# M2354 register map
File version: 1.0
Registers are 32-bit, read-write, reset 0x0 unless marked. A register's access mark holds for its fields unless they carry their own. Offsets are from the block's base; [hi:lo] are bit positions; {n}, {i} and the like mark numbered series.

## KS — KS Register Map
Base 0x40035000
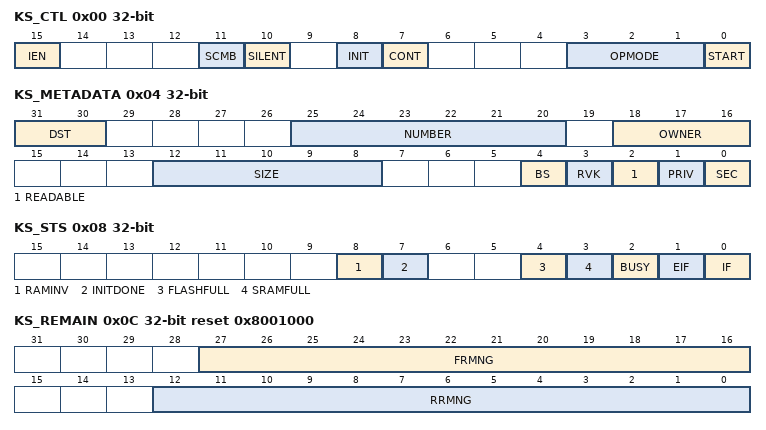
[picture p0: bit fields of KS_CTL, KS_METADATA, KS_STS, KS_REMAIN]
0x00 KS_CTL — Key Store Control Register
  [15] IEN — Key Store Interrupt Enable Bit
    0=Key Store Interrupt Disabled; 1=Key Store Interrupt Enabled
  [11] SCMB — Data Scramble Enable Bit
    0=Data Scramble Disabled; 1=Data Scramble Enabled
  [10] SILENT — Silent Access Enable Bit
    0=Silent Access Disabled; 1=Silent Access Enabled
  [8] INIT — Key Store Initialization. User should to check BUSY(KS_STS[2]) is 0, and then write 1 to this bit and START(KS_CTL[0[), the Key Store will start to be initialized. After Key Store is initialized, INIT will be cleared. Note: Before executing INIT, user must check KS(SYS_SRAMPC1) is 00.
  [7] CONT — Read/Write Key Continue Bit
    0=Read/Write key operation is not continuous to previous operation; 1=Read/Write key operation is continuous to previous operation
  [3:1] OPMODE — Key Store Operation Mode
    0=Read operation; 1=Create operation; 2=Erase one key operation (only for key is in SRAM); 3=Erase all keys operation (only for SRAM and Flash); 4=Revoke key operation; 5=Data Remanence prevention operation (only for SRAM)
  [0] START — Key Store Start Control Bit
    0=No operation; 1=Start the operation
0x04 KS_METADATA — Key Store Metadata Register
  [31:30] DST — Key Location Selection Bits
    0=Key is in SRAM; 1=Key is in Flash; 2=Key is in OTP
  [25:20] NUMBER — Key Number. Before read or erase one key operation starts, user should write the key number to be operated. When create operation is finished, user can read these bits to get its key number.
  [18:16] OWNER — Key Owner Selection Bits
    0=Only for AES used; 1=Only for HMAC engine used; 2=Only for RSA engine exponential used (private key); 3=Only for RSA engine middle data used; 4=Only for ECC engine used; 5=Only for CPU engine use
  [12:8] SIZE — Key Size Selection Bits
    0=128 bits; 1=163 bits; 2=192 bits; 3=224 bits; 4=233 bits; 5=255 bits; 6=256 bits; 7=283 bits; 8=384 bits; 9=409 bits; 10=512 bits; 11=521 bits; 12=571 bits; 16=1024 bits; 17=1536 bits; 18=2048 bits; 19=3072 bits; 20=4096 bits
  [4] BS — Booting State Selection Bit
    0=Set key used at all state; 1=Set key used at boot loader state 1 (BL1 state)
  [3] RVK — Key Revoke Control Bit
    0=Key current selected will not be changed; 1=key current selected will be change to revoked state
  [2] READABLE — Key Readable Control Bit
    0=key is un-readable; 1=key is readable
  [1] PRIV — Privilege Key Selection Bit
    0=Set key as the non-privilege key; 1=Set key as the privilege key
  [0] SEC — Secure Key Selection Bit
    0=Set key as the non-secure key; 1=Set key as the secure key
0x08 KS_STS — Key Store Status Register
  [8] RAMINV ro — Key Store SRAM Invert Status (Read Only)
    0=Key Store key in SRAM is normal; 1=Key Store key in SRAM is inverted
  [7] INITDONE ro — Key Store Initialization Done Status (Read Only)
    0=Key Store is un-initialized; 1=Key Store is initialized
  [4] FLASHFULL ro — Key Storage at Flash Full Status Bit (Read Only)
    0=Key Storage at Flash is not full; 1=Key Storage at Flash is full
  [3] SRAMFULL ro — Key Storage at SRAM Full Status Bit (read only)
    0=Key Storage at SRAM is not full; 1=Key Storage at SRAM is full
  [2] BUSY ro — Key Store Busy Flag (read only)
    0=Key Store is idle or finished; 1=Key Store is busy
  [1] EIF — Key Store Error Flag. This bit is cleared by writing 1 and it has no effect by writing 0.
    0=No Key Store error; 1=Key Store error interrupt
  [0] IF — Key Store Finish Interrupt Flag. This bit is cleared by writing 1 and it has no effect by writing 0.
    0=No Key Store interrupt; 1=Key Store operation done interrupt
0x0C KS_REMAIN ro reset 0x8001000 — Key Store Remaining Space Register
  [27:16] FRMNG — Key Store Flash Remaining Space. The FRMNG shows the remaining byte count space for Flash.
  [12:0] RRMNG — Key Store SRAM Remaining Space. The RRMNG shows the remaining byte count space for SRAM.
{0x10+4i} KS_SCMBKEY{i} (i=0..3) — Key Store Scramble Key Word {i} Register
  [31:0] SCMBKEY — Key Store Scramble Key. When SCMB(KS_CTL[]) is set to 1, user should write the scramble key in this register before new key stores in Key Store. If user does not write the scramble key in this register, the Key Store will use previous scramble key to execute data scramble function.
{0x20+4i} KS_KEY{i} (i=0..7) — Key Store Entry Key Word {i} Register
  [31:0] KEY — Key Data. The register will be cleared if the Key Store executes the write operation or CPU completes the reading key.
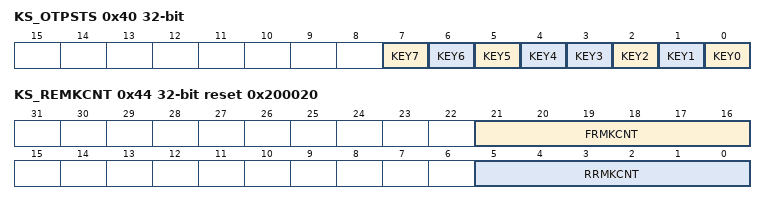
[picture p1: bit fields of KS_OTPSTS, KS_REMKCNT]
0x40 KS_OTPSTS ro — Key Store OTP Keys Status Register
  [7] KEY7 — OTP Key 7 Used Status. Note: If chip is changed to RMA stage, the existing key will be revoked after initialization.
    0=OTP key 7 is unused; 1=OTP key 7 is used
  [6] KEY6 — OTP Key 6 Used Status. Note: If chip is changed to RMA stage, the existing key will be revoked after initialization.
    0=OTP key 6 is unused; 1=OTP key 6 is used
  [5] KEY5 — OTP Key 5 Used Status. Note: If chip is changed to RMA stage, the existing key will be revoked after initialization.
    0=OTP key 5 is unused; 1=OTP key 5 is used
  [4] KEY4 — OTP Key 4 Used Status. Note: If chip is changed to RMA stage, existing key will be revoked after initialization.
    0=OTP key 4 is unused; 1=OTP key 4 is used
  [n] KEY{n} (n=0..3) — OTP Key {n} Used Status. Note: If chip is changed to RMA stage, the existing key will be revoked after initialization.
    0=OTP key {n} is unused; 1=OTP key {n} is used
0x44 KS_REMKCNT ro reset 0x200020 — Key Store Remaining Key Count Register
  [21:16] FRMKCNT — Key Store Flash Remaining Key Count. The FRMKCNT shows the remaining key count for Flash.
  [5:0] RRMKCNT — Key Store SRAM Remaining Key Count. The RRMKCNT shows the remaining key count for SRAM.
